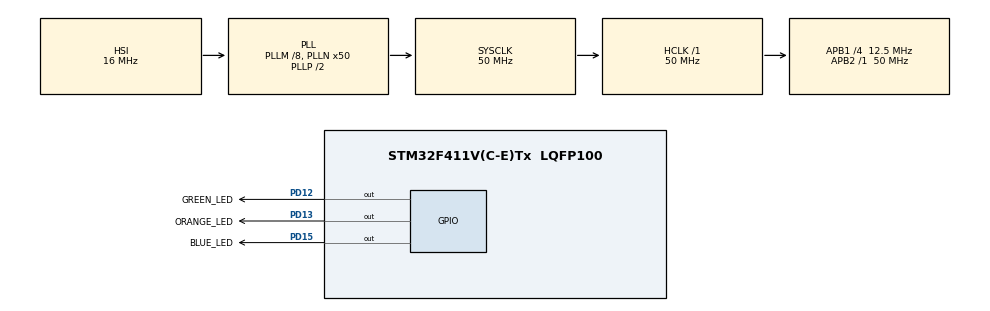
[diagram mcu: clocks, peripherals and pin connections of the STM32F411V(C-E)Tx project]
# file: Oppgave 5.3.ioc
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FREERTOS.Queues01=myQ1,8,uint16_t,0,Dynamic,NULL,NULL
FREERTOS.Tasks01=ProducerTask,0,128,StartProducerTask,Default,NULL,Dynamic,NULL,NULL;ConsumerTask,0,128,StartConsumerTask,Default,NULL,Dynamic,NULL,NULL
Mcu.Family=STM32F4
Mcu.Name=STM32F411V(C-E)Tx
Mcu.Package=LQFP100
NVIC.PriorityGroup=NVIC_PRIORITYGROUP_4
PD12.GPIO_Label=GREEN_LED
PD12.Signal=GPIO_Output
PD13.GPIO_Label=ORANGE_LED
PD13.Signal=GPIO_Output
PD15.GPIO_Label=BLUE_LED
PD15.Signal=GPIO_Output
ProjectManager.HeapSize=0x200
ProjectManager.StackSize=0x400
ProjectManager.TargetToolchain=STM32CubeIDE
RCC.48MHZClocksFreq_Value=12500000
RCC.AHBFreq_Value=50000000
RCC.APB1CLKDivider=RCC_HCLK_DIV4
RCC.APB1Freq_Value=12500000
RCC.APB1TimFreq_Value=25000000
RCC.APB2Freq_Value=50000000
RCC.APB2TimFreq_Value=50000000
RCC.CortexFreq_Value=50000000
RCC.HCLKFreq_Value=50000000
RCC.HSE_VALUE=8000000
RCC.HSI_VALUE=16000000
RCC.LSE_VALUE=32768
RCC.PLLI2SM=5
RCC.PLLI2SN=200
RCC.PLLM=8
RCC.PLLN=50
RCC.PLLQ=8
RCC.SYSCLKFreq_VALUE=50000000
RCC.SYSCLKSource=RCC_SYSCLKSOURCE_PLLCLK
RCC.VCOOutputFreq_Value=100000000
VP_FREERTOS_VS_CMSIS_V1.Mode=CMSIS_V1
board=STM32F411E-DISCO

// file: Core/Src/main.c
/* USER CODE BEGIN Header */
/**
  ******************************************************************************
  * @file           : main.c
  * @brief          : Main program body
  ******************************************************************************
  * @attention
  *
  * Copyright (c) 2024 STMicroelectronics.
  * All rights reserved.
  *
  * This software is licensed under terms that can be found in the LICENSE file
  * in the root directory of this software component.
  * If no LICENSE file comes with this software, it is provided AS-IS.
  *
  ******************************************************************************
  */
/* USER CODE END Header */
#include "main.h"
#include "cmsis_os.h"

osThreadId ProducerTaskHandle;
osThreadId ConsumerTaskHandle;
osMessageQId myQ1Handle;

void SystemClock_Config(void);
static void MX_GPIO_Init(void);
void StartProducerTask(void const * argument);
void StartConsumerTask(void const * argument);

int main(void)
{

  /* MCU Configuration--------------------------------------------------------*/

  /* Reset of all peripherals, Initializes the Flash interface and the Systick. */
  HAL_Init();

  /* Configure the system clock */
  SystemClock_Config();

  /* Initialize all configured peripherals */
  MX_GPIO_Init();

  /* Create the queue(s) */
  /* definition and creation of myQ1 */
  osMessageQDef(myQ1, 8, uint16_t);
  myQ1Handle = osMessageCreate(osMessageQ(myQ1), NULL);

  /* Create the thread(s) */
  /* definition and creation of ProducerTask */
  osThreadDef(ProducerTask, StartProducerTask, osPriorityNormal, 0, 128);
  ProducerTaskHandle = osThreadCreate(osThread(ProducerTask), NULL);

  /* definition and creation of ConsumerTask */
  osThreadDef(ConsumerTask, StartConsumerTask, osPriorityNormal, 0, 128);
  ConsumerTaskHandle = osThreadCreate(osThread(ConsumerTask), NULL);

  /* Start scheduler */
  osKernelStart();

  /* We should never get here as control is now taken by the scheduler */

  /* Infinite loop */
  while (1)
  {

  }
}

void SystemClock_Config(void)
{
  RCC_OscInitTypeDef RCC_OscInitStruct = {0};
  RCC_ClkInitTypeDef RCC_ClkInitStruct = {0};

  /** Configure the main internal regulator output voltage
  */
  __HAL_RCC_PWR_CLK_ENABLE();
  __HAL_PWR_VOLTAGESCALING_CONFIG(PWR_REGULATOR_VOLTAGE_SCALE1);

  /** Initializes the RCC Oscillators according to the specified parameters
  * in the RCC_OscInitTypeDef structure.
  */
  RCC_OscInitStruct.OscillatorType = RCC_OSCILLATORTYPE_HSI;
  RCC_OscInitStruct.HSIState = RCC_HSI_ON;
  RCC_OscInitStruct.HSICalibrationValue = RCC_HSICALIBRATION_DEFAULT;
  RCC_OscInitStruct.PLL.PLLState = RCC_PLL_ON;
  RCC_OscInitStruct.PLL.PLLSource = RCC_PLLSOURCE_HSI;
  RCC_OscInitStruct.PLL.PLLM = 8;
  RCC_OscInitStruct.PLL.PLLN = 50;
  RCC_OscInitStruct.PLL.PLLP = RCC_PLLP_DIV2;
  RCC_OscInitStruct.PLL.PLLQ = 8;
  if (HAL_RCC_OscConfig(&RCC_OscInitStruct) != HAL_OK)
  {
    Error_Handler();
  }

  /** Initializes the CPU, AHB and APB buses clocks
  */
  RCC_ClkInitStruct.ClockType = RCC_CLOCKTYPE_HCLK|RCC_CLOCKTYPE_SYSCLK
                              |RCC_CLOCKTYPE_PCLK1|RCC_CLOCKTYPE_PCLK2;
  RCC_ClkInitStruct.SYSCLKSource = RCC_SYSCLKSOURCE_PLLCLK;
  RCC_ClkInitStruct.AHBCLKDivider = RCC_SYSCLK_DIV1;
  RCC_ClkInitStruct.APB1CLKDivider = RCC_HCLK_DIV4;
  RCC_ClkInitStruct.APB2CLKDivider = RCC_HCLK_DIV1;

  if (HAL_RCC_ClockConfig(&RCC_ClkInitStruct, FLASH_LATENCY_1) != HAL_OK)
  {
    Error_Handler();
  }
}

static void MX_GPIO_Init(void)
{
  GPIO_InitTypeDef GPIO_InitStruct = {0};

  /* GPIO Ports Clock Enable */
  __HAL_RCC_GPIOD_CLK_ENABLE();

  /*Configure GPIO pin Output Level */
  HAL_GPIO_WritePin(GPIOD, GREEN_LED_Pin|ORANGE_LED_Pin|BLUE_LED_Pin, GPIO_PIN_RESET);

  /*Configure GPIO pins : GREEN_LED_Pin ORANGE_LED_Pin BLUE_LED_Pin */
  GPIO_InitStruct.Pin = GREEN_LED_Pin|ORANGE_LED_Pin|BLUE_LED_Pin;
  GPIO_InitStruct.Mode = GPIO_MODE_OUTPUT_PP;
  GPIO_InitStruct.Pull = GPIO_NOPULL;
  GPIO_InitStruct.Speed = GPIO_SPEED_FREQ_LOW;
  HAL_GPIO_Init(GPIOD, &GPIO_InitStruct);

}

void StartProducerTask(void const * argument)
{
  /* USER CODE BEGIN 5 */
	/* This function is what should be added to the queue */

	// 3 pieces of data to be added to the queue
	uint32_t data1 = 1; // Green LED
	uint32_t data2 = 3; // Orange LED
	uint32_t data3 = 5; // Blue LED

  /* Infinite loop */
  for(;;)
  {
	  // Put 3 messages in the queue
	  osMessagePut(myQ1Handle, data1, osWaitForever);
	  osDelay(1000);

	  osMessagePut(myQ1Handle, data2, osWaitForever);
	  osDelay(1000);

	  osMessagePut(myQ1Handle, data3, osWaitForever);
	  osDelay(1000);
  }
  /* USER CODE END 5 */
}

void StartConsumerTask(void const * argument)
{
  /* USER CODE BEGIN StartConsumerTask */
	/* This function is what should be done with the items in the queue */

	// Declaring an osEvent
	osEvent event;

  /* Infinite loop */
  for(;;)
  {
	  // Retrieve message from the queue
	  event = osMessageGet(myQ1Handle, osWaitForever);

	  // If the event contains a message, blink the blue LED according to the # retrieved from the queue
	  if (event.status == osEventMessage){
		  uint16_t blink_count = event.value.v; // Get the value of the message

		  /* Original task code */

//		  while(blink_count--){
//			  HAL_GPIO_TogglePin(BLUE_LED_GPIO_Port, BLUE_LED_Pin);
//			  osDelay(100);
//		  }

		  /* Own code, adding to functionality */
		  if (event.value.v == 1){
			  while(blink_count--){
				  HAL_GPIO_TogglePin(GREEN_LED_GPIO_Port, GREEN_LED_Pin);
				  osDelay(100);
				  HAL_GPIO_TogglePin(GREEN_LED_GPIO_Port, GREEN_LED_Pin);
				  osDelay(100);
			  }
		  } else if (event.value.v == 3){
			  while(blink_count--){
				  HAL_GPIO_TogglePin(ORANGE_LED_GPIO_Port, ORANGE_LED_Pin);
				  osDelay(100);
				  HAL_GPIO_TogglePin(ORANGE_LED_GPIO_Port, ORANGE_LED_Pin);
				  osDelay(100);
			  }
		  } else if (event.value.v == 5){
			  while(blink_count--){
				  HAL_GPIO_TogglePin(BLUE_LED_GPIO_Port, BLUE_LED_Pin);
				  osDelay(100);
				  HAL_GPIO_TogglePin(BLUE_LED_GPIO_Port, BLUE_LED_Pin);
				  osDelay(100);
			  }
		  }
	  }
  }
  /* USER CODE END StartConsumerTask */
}

void Error_Handler(void)
{
  __disable_irq();
  while (1)
  {
  }
}
